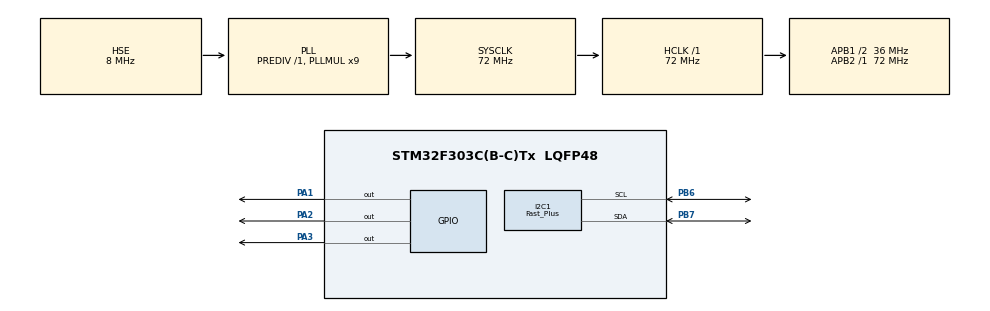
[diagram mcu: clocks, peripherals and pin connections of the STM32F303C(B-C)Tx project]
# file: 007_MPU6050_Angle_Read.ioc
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I2C1.I2C_Speed_Mode=I2C_Fast_Plus
I2C1.Timing=0x00000001
Mcu.Family=STM32F3
Mcu.Name=STM32F303C(B-C)Tx
Mcu.Package=LQFP48
NVIC.PriorityGroup=NVIC_PRIORITYGROUP_4
PA1.Signal=GPIO_Output
PA13.Mode=Trace_Asynchronous_SW
PA13.Signal=SYS_JTMS-SWDIO
PA14.Mode=Trace_Asynchronous_SW
PA14.Signal=SYS_JTCK-SWCLK
PA2.Signal=GPIO_Output
PA3.Signal=GPIO_Output
PB3.Mode=Trace_Asynchronous_SW
PB3.Signal=SYS_JTDO-TRACESWO
PB6.Mode=I2C
PB6.Signal=I2C1_SCL
PB7.Mode=I2C
PB7.Signal=I2C1_SDA
PF0-OSC_IN.Mode=HSE-External-Oscillator
PF0-OSC_IN.Signal=RCC_OSC_IN
PF1-OSC_OUT.Mode=HSE-External-Oscillator
PF1-OSC_OUT.Signal=RCC_OSC_OUT
ProjectManager.HeapSize=0x200
ProjectManager.StackSize=0x400
ProjectManager.TargetToolchain=STM32CubeIDE
RCC.AHBFreq_Value=72000000
RCC.APB1CLKDivider=RCC_HCLK_DIV2
RCC.APB1Freq_Value=36000000
RCC.APB1TimFreq_Value=72000000
RCC.APB2Freq_Value=72000000
RCC.APB2TimFreq_Value=72000000
RCC.CortexFreq_Value=72000000
RCC.HCLKFreq_Value=72000000
RCC.HSE_VALUE=8000000
RCC.HSI_VALUE=8000000
RCC.LSE_VALUE=32768
RCC.PLLMUL=RCC_PLL_MUL9
RCC.PLLSourceVirtual=RCC_PLLSOURCE_HSE
RCC.SYSCLKFreq_VALUE=72000000
RCC.SYSCLKSourceVirtual=RCC_SYSCLKSOURCE_PLLCLK
RCC.USBFreq_Value=72000000
board=custom

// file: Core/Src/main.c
/* USER CODE BEGIN Header */
/**
  ******************************************************************************
  * @file           : main.c
  * @brief          : Main program body
  ******************************************************************************
  * @attention
  *
  * Copyright (c) 2024 STMicroelectronics.
  * All rights reserved.
  *
  * This software is licensed under terms that can be found in the LICENSE file
  * in the root directory of this software component.
  * If no LICENSE file comes with this software, it is provided AS-IS.
  *
  ******************************************************************************
  */
/* USER CODE END Header */
#include "main.h"

/* USER CODE BEGIN Includes */
#include <stdio.h>
#include <math.h>
#include "mpu6050.h"
#include "led.h"
/* USER CODE END Includes */

I2C_HandleTypeDef hi2c1;

/* USER CODE BEGIN PV */
double degreex, degreey;
/* USER CODE END PV */

void SystemClock_Config(void);
static void MX_GPIO_Init(void);
static void MX_I2C1_Init(void);

int main(void)
{

  /* MCU Configuration--------------------------------------------------------*/

  /* Reset of all peripherals, Initializes the Flash interface and the Systick. */
  HAL_Init();

  /* Configure the system clock */
  SystemClock_Config();

  /* Initialize all configured peripherals */
  MX_GPIO_Init();
  MX_I2C1_Init();
  /* USER CODE BEGIN 2 */
  /* Initialize the MPU6050 sensor */
  mpu6050_init();
  /* USER CODE END 2 */

  /* Infinite loop */
  while (1)
  {

    /* USER CODE BEGIN 3 */
    /* Read sensor data from the MPU6050 */
    mpu6050_read();
    /* Check conditions to turn on/off LEDs based on sensor readings */
    led_on();
  }
  /* USER CODE END 3 */
}

void SystemClock_Config(void)
{
  RCC_OscInitTypeDef RCC_OscInitStruct = {0};
  RCC_ClkInitTypeDef RCC_ClkInitStruct = {0};
  RCC_PeriphCLKInitTypeDef PeriphClkInit = {0};

  /** Initializes the RCC Oscillators according to the specified parameters
  * in the RCC_OscInitTypeDef structure.
  */
  RCC_OscInitStruct.OscillatorType = RCC_OSCILLATORTYPE_HSI|RCC_OSCILLATORTYPE_HSE;
  RCC_OscInitStruct.HSEState = RCC_HSE_ON;
  RCC_OscInitStruct.HSEPredivValue = RCC_HSE_PREDIV_DIV1;
  RCC_OscInitStruct.HSIState = RCC_HSI_ON;
  RCC_OscInitStruct.HSICalibrationValue = RCC_HSICALIBRATION_DEFAULT;
  RCC_OscInitStruct.PLL.PLLState = RCC_PLL_ON;
  RCC_OscInitStruct.PLL.PLLSource = RCC_PLLSOURCE_HSE;
  RCC_OscInitStruct.PLL.PLLMUL = RCC_PLL_MUL9;
  if (HAL_RCC_OscConfig(&RCC_OscInitStruct) != HAL_OK)
  {
    Error_Handler();
  }

  /** Initializes the CPU, AHB and APB buses clocks
  */
  RCC_ClkInitStruct.ClockType = RCC_CLOCKTYPE_HCLK|RCC_CLOCKTYPE_SYSCLK
                              |RCC_CLOCKTYPE_PCLK1|RCC_CLOCKTYPE_PCLK2;
  RCC_ClkInitStruct.SYSCLKSource = RCC_SYSCLKSOURCE_PLLCLK;
  RCC_ClkInitStruct.AHBCLKDivider = RCC_SYSCLK_DIV1;
  RCC_ClkInitStruct.APB1CLKDivider = RCC_HCLK_DIV2;
  RCC_ClkInitStruct.APB2CLKDivider = RCC_HCLK_DIV1;

  if (HAL_RCC_ClockConfig(&RCC_ClkInitStruct, FLASH_LATENCY_2) != HAL_OK)
  {
    Error_Handler();
  }
  PeriphClkInit.PeriphClockSelection = RCC_PERIPHCLK_I2C1;
  PeriphClkInit.I2c1ClockSelection = RCC_I2C1CLKSOURCE_HSI;
  if (HAL_RCCEx_PeriphCLKConfig(&PeriphClkInit) != HAL_OK)
  {
    Error_Handler();
  }
}

static void MX_I2C1_Init(void)
{

  hi2c1.Instance = I2C1;
  hi2c1.Init.Timing = 0x00000001;
  hi2c1.Init.OwnAddress1 = 0;
  hi2c1.Init.AddressingMode = I2C_ADDRESSINGMODE_7BIT;
  hi2c1.Init.DualAddressMode = I2C_DUALADDRESS_DISABLE;
  hi2c1.Init.OwnAddress2 = 0;
  hi2c1.Init.OwnAddress2Masks = I2C_OA2_NOMASK;
  hi2c1.Init.GeneralCallMode = I2C_GENERALCALL_DISABLE;
  hi2c1.Init.NoStretchMode = I2C_NOSTRETCH_DISABLE;
  if (HAL_I2C_Init(&hi2c1) != HAL_OK)
  {
    Error_Handler();
  }

  /** Configure Analogue filter
  */
  if (HAL_I2CEx_ConfigAnalogFilter(&hi2c1, I2C_ANALOGFILTER_ENABLE) != HAL_OK)
  {
    Error_Handler();
  }

  /** Configure Digital filter
  */
  if (HAL_I2CEx_ConfigDigitalFilter(&hi2c1, 0) != HAL_OK)
  {
    Error_Handler();
  }

  /** I2C Fast mode Plus enable
  */
  __HAL_SYSCFG_FASTMODEPLUS_ENABLE(I2C_FASTMODEPLUS_I2C1);

}

static void MX_GPIO_Init(void)
{
  GPIO_InitTypeDef GPIO_InitStruct = {0};

  /* GPIO Ports Clock Enable */
  __HAL_RCC_GPIOF_CLK_ENABLE();
  __HAL_RCC_GPIOA_CLK_ENABLE();
  __HAL_RCC_GPIOB_CLK_ENABLE();

  /*Configure GPIO pin Output Level */
  HAL_GPIO_WritePin(GPIOA, GPIO_PIN_1|GPIO_PIN_2|GPIO_PIN_3, GPIO_PIN_RESET);

  /*Configure GPIO pins : PA1 PA2 PA3 */
  GPIO_InitStruct.Pin = GPIO_PIN_1|GPIO_PIN_2|GPIO_PIN_3;
  GPIO_InitStruct.Mode = GPIO_MODE_OUTPUT_PP;
  GPIO_InitStruct.Pull = GPIO_NOPULL;
  GPIO_InitStruct.Speed = GPIO_SPEED_FREQ_LOW;
  HAL_GPIO_Init(GPIOA, &GPIO_InitStruct);

}

void Error_Handler(void)
{
  __disable_irq();
  while (1)
  {
  }
}
